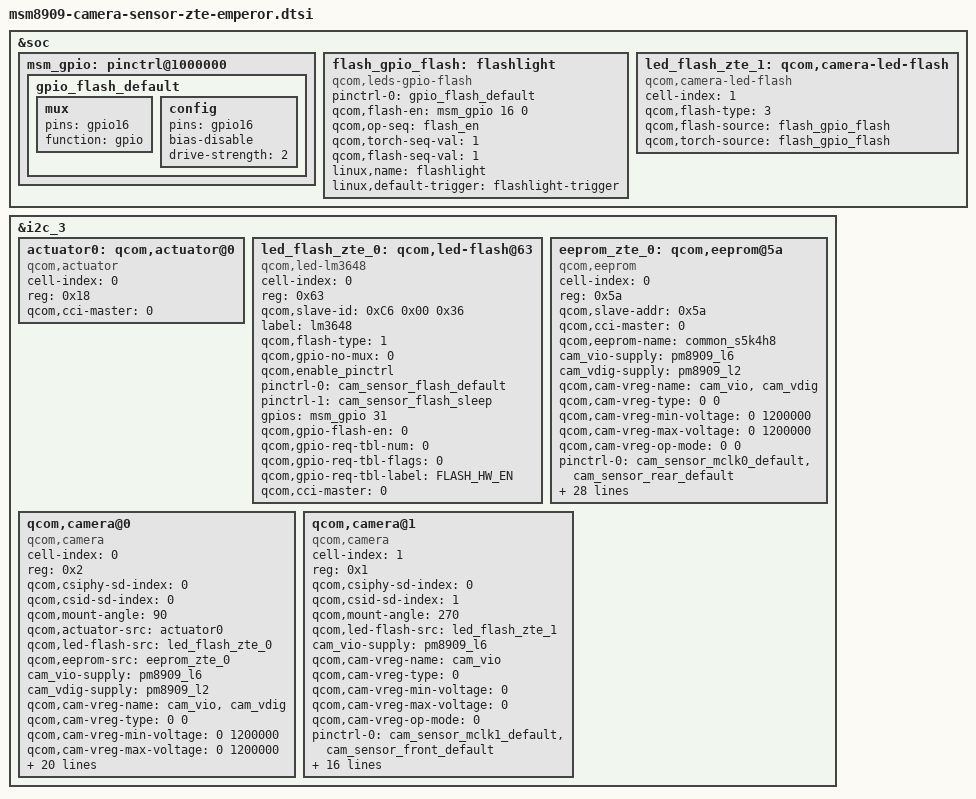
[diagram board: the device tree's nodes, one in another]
/*
 * Copyright (c) 2014-2015, The Linux Foundation. All rights reserved.
 *
 * This program is free software; you can redistribute it and/or modify
 * it under the terms of the GNU General Public License version 2 and
 * only version 2 as published by the Free Software Foundation.
 *
 * This program is distributed in the hope that it will be useful,
 * but WITHOUT ANY WARRANTY; without even the implied warranty of
 * MERCHANTABILITY or FITNESS FOR A PARTICULAR PURPOSE.  See the
 * GNU General Public License for more details.
 */
&soc {
	msm_gpio: pinctrl@1000000 {
		gpio_flash_default: gpio_flash_default {
			mux {
				/* CLK, DATA */
				pins = "gpio16";
				function = "gpio";
			};
			config {
				pins = "gpio16";
				bias-disable; /* No PULL */
				drive-strength = <2>; /* 2 MA */
			};
		};
	};
	flash_gpio_flash:flashlight {
		compatible = "qcom,leds-gpio-flash";
		status = "okay";
		pinctrl-names = "flash_default";
		pinctrl-0 = <&gpio_flash_default>;
		qcom,flash-en = <&msm_gpio 16 0>;
		qcom,op-seq = "flash_en";
		qcom,torch-seq-val = <1>;
		qcom,flash-seq-val = <1>;
		linux,name = "flashlight";
		linux,default-trigger = "flashlight-trigger";
	};
	led_flash_zte_1: qcom,camera-led-flash {
		cell-index = <1>;
		compatible = "qcom,camera-led-flash";
		qcom,flash-type = <3>;
		qcom,flash-source = <&flash_gpio_flash>;
		qcom,torch-source = <&flash_gpio_flash>;
	};
};
&i2c_3 {
	actuator0: qcom,actuator@0 {
		cell-index = <0>;
		reg = <0x18>;
		compatible = "qcom,actuator";
		qcom,cci-master = <0>;
	};
	led_flash_zte_0: qcom,led-flash@63 {
		cell-index = <0>;
		reg = <0x63>;
		qcom,slave-id = <0xC6 0x00 0x36>;
		compatible = "qcom,led-lm3648";
		label = "lm3648";
		qcom,flash-type = <1>;
		qcom,gpio-no-mux = <0>;
		qcom,enable_pinctrl;
		pinctrl-names = "cam_flash_default", "cam_flash_suspend";
		pinctrl-0 = <&cam_sensor_flash_default>;
		pinctrl-1 = <&cam_sensor_flash_sleep>;
		gpios = <&msm_gpio 31 0>;
		qcom,gpio-flash-en = <0>;
		qcom,gpio-req-tbl-num = <0>;
		qcom,gpio-req-tbl-flags = <0>;
		qcom,gpio-req-tbl-label = "FLASH_HW_EN";
		qcom,cci-master = <0>;
	};
	/* Added s5k4h8 eeprom device node*/
	eeprom_zte_0: qcom,eeprom@5a{
		compatible = "qcom,eeprom";
		cell-index = <0>;
		reg = <0x5a>;
		qcom,slave-addr = <0x5a>;
		qcom,cci-master = <0>;
		qcom,eeprom-name = "common_s5k4h8";
		cam_vio-supply = <&pm8909_l6>;
		cam_vdig-supply = <&pm8909_l2>;
		qcom,cam-vreg-name = "cam_vio", "cam_vdig";
		qcom,cam-vreg-type = <0 0>;
		qcom,cam-vreg-min-voltage = <0 1200000>;
		qcom,cam-vreg-max-voltage = <0 1200000>;
		qcom,cam-vreg-op-mode = <0 0>;
		pinctrl-names = "cam_default", "cam_suspend";
		pinctrl-0 = <&cam_sensor_mclk0_default	&cam_sensor_rear_default>;
		pinctrl-1 = <&cam_sensor_mclk0_sleep &cam_sensor_rear_sleep>;
		gpios = <&msm_gpio 26 0>,
				<&msm_gpio 35 0>,
				<&msm_gpio 17 0>;
		qcom,gpio-reset = <1>;
		qcom,gpio-vana = <2>;
		qcom,gpio-req-tbl-num = <0 1 2>;
		qcom,gpio-req-tbl-flags = <1 0 0>;
		qcom,gpio-req-tbl-label = "CAMIF_MCLK",
				"CAM_RESET1",
				"CAM_VANA";
		qcom,cam-power-seq-type = "sensor_gpio",
				"sensor_gpio",
				"sensor_gpio",
				"sensor_gpio",
				"sensor_gpio",
				"sensor_clk",
				"sensor_i2c_mux";
		qcom,cam-power-seq-val = "sensor_gpio_standby",
				"sensor_gpio_reset",
				"sensor_gpio_vana",
				"sensor_gpio_standby",
				"sensor_gpio_reset",
				"sensor_cam_mclk",
				"none";
		qcom,cam-power-seq-cfg-val = < 0 0 1 1 1 24000000 0>;
		qcom,cam-power-seq-delay =   < 1 1 3 1 1 10 0>;
		zte,num-blocks = <5>;
		zte,mem0 = <1 0x0a3e 2 0x0 1 0>; //lsc  FLAG
		zte,mem1 = <20 0x0a04 2 0x0 1 0>; //AWB group1 flag1 no checksum
		zte,mem2 = <20 0x0a1a 2 0x0 1 0>; //AWB group2 flag2 no checksum
		zte,mem3 = <4 0x0a31 2 0x0 1 0>; //AF group1 no flag1 no checksum
		zte,mem4 = <4 0x0a38 2 0x0 1 0>; //AF group2 no flag2 no checksum
		clocks = <&clock_gcc clk_mclk0_clk_src>,
				<&clock_gcc clk_gcc_camss_mclk0_clk>;
		clock-names = "cam_src_clk", "cam_clk";
		qcom,clock-rates = <24000000 0>;
		status = "ok";
	};
	qcom,camera@0 {
		cell-index = <0>;
		compatible = "qcom,camera";
		reg = <0x2>;
		qcom,csiphy-sd-index = <0>;
		qcom,csid-sd-index = <0>;
		qcom,mount-angle = <90>;
		qcom,actuator-src = <&actuator0>;
		qcom,led-flash-src = <&led_flash_zte_0>;
		qcom,eeprom-src = <&eeprom_zte_0>;
		cam_vio-supply = <&pm8909_l6>;
		cam_vdig-supply = <&pm8909_l2>;
		qcom,cam-vreg-name = "cam_vio", "cam_vdig";
		qcom,cam-vreg-type = <0 0>;
		qcom,cam-vreg-min-voltage = <0 1200000>;
		qcom,cam-vreg-max-voltage = <0 1200000>;
		qcom,cam-vreg-op-mode = <0 0>;
		pinctrl-names = "cam_default", "cam_suspend";
		pinctrl-0 = <&cam_sensor_mclk0_default
				&cam_sensor_rear_default>;
		pinctrl-1 = <&cam_sensor_mclk0_sleep &cam_sensor_rear_sleep>;
		gpios = <&msm_gpio 26 0>,
				<&msm_gpio 35 0>,
				<&msm_gpio 17 0>,
				<&msm_gpio 71 0>;
		qcom,gpio-reset = <1>;
		qcom,gpio-vana = <2>;
		qcom,gpio-vaf = <3>;
		qcom,gpio-req-tbl-num = <0 1 2 3>;
		qcom,gpio-req-tbl-flags = <1 0 0 0>;
		qcom,gpio-req-tbl-label = "CAMIF_MCLK",
				"CAM_RESET1",
				"CAM_VANA",
				"CAM_VAF";
		qcom,sensor-position = <0>;
		qcom,sensor-mode = <0>;
		qcom,cci-master = <0>;
		status = "ok";
		clocks = <&clock_gcc clk_mclk0_clk_src>,
				<&clock_gcc clk_gcc_camss_mclk0_clk>;
		clock-names = "cam_src_clk", "cam_clk";
		qcom,clock-rates = <24000000 0>;
	};
	qcom,camera@1 {
		cell-index = <1>;
		compatible = "qcom,camera";
		reg = <0x1>;
		qcom,csiphy-sd-index = <0>;
		qcom,csid-sd-index = <1>;
		qcom,mount-angle= <270>;
		qcom,led-flash-src = <&led_flash_zte_1>;
		cam_vio-supply = <&pm8909_l6>;
		qcom,cam-vreg-name = "cam_vio";
		qcom,cam-vreg-type = <0>;
		qcom,cam-vreg-min-voltage= <0>;
		qcom,cam-vreg-max-voltage = <0>;
		qcom,cam-vreg-op-mode = <0>;
		pinctrl-names = "cam_default", "cam_suspend";
		pinctrl-0 = <&cam_sensor_mclk1_default &cam_sensor_front_default>;
		pinctrl-1 = <&cam_sensor_mclk1_sleep &cam_sensor_front_sleep>;
		gpios = <&msm_gpio 27 0>,
				<&msm_gpio 28 0>,
				<&msm_gpio 65 0>,
				<&msm_gpio 36 0>,
				<&msm_gpio 17 0>;
		qcom,gpio-reset = <1>;
		qcom,gpio-standby = <2>;
				qcom,gpio-vdig = <3>;
				qcom,gpio-vana = <4>;
				qcom,gpio-req-tbl-num = <0 1 2 3 4>;
				qcom,gpio-req-tbl-flags = <1 0 0 0 0>;
		qcom,gpio-req-tbl-label = "CAMIF_MCLK",
				"CAM_RESET",
				"CAM_STANDBY",
				"CAM_VDIG",
				"CAM_VANA";
		status = "ok";
		qcom,cci-master = <0>;
		clocks = <&clock_gcc clk_mclk1_clk_src>,
				<&clock_gcc clk_gcc_camss_mclk1_clk>;
		clock-names = "cam_src_clk", "cam_clk";
		qcom,clock-rates = <24000000 0>;
		};
};
